# eCOMP0_445 register map
Vendor: Texas Instruments
Peripheral module from a debugger description file (folder msp430).
Registers are 16-bit, read-write, no defined reset value unless marked. A register's access mark holds for its fields unless they carry their own. Offsets are as the file gives them; lines under a group give offsets from that group; [hi:lo] are bit positions; {n}, {i} and the like mark numbered series; 'fields as' and 'values as' point back to an identical list; <NAME> marks a mode.

## eCOMP0
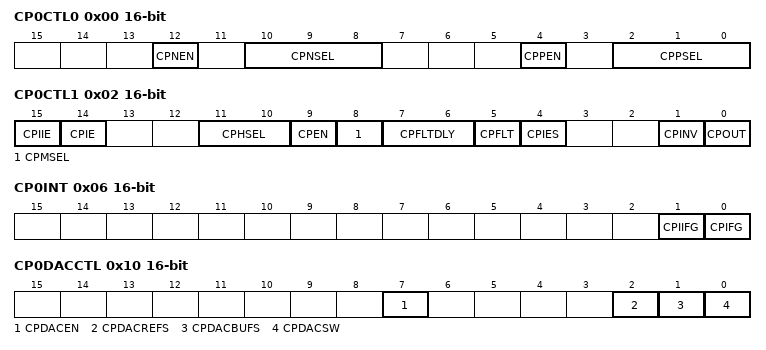
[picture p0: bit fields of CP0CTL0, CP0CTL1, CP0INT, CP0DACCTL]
0x00 CP0CTL0 — Comparator Control Register 0
  [12] CPNEN — Channel input enable for the - terminal
    0=Selected analog input channel for V- terminal is disabled; 1=Selected analog input channel for V- terminal is enabled
  [10:8] CPNSEL — Channel input selected for the - terminal
    {v}=select external input source (v=0..3); 4=device specific, please refer to device data sheet for details; 5=device specific, please refer to device data sheet for details; 6=6-bit DAC
  [4] CPPEN — Channel input enable for the V+ terminal
    0=Selected analog input channel for V+ terminal is disabled; 1=Selected analog input channel for V+ terminal is enabled
  [2:0] CPPSEL — Channel input selected for the V+ terminal
    values as CPNSEL
0x02 CP0CTL1 access per field — Comparator Control Register 1
  [15] CPIIE rw — Comparator inverted interrupt output enable bit
    0=Interrupt inverted output is disabled; 1=Interrupt inverted output is enabled
  [14] CPIE rw — Comparator interrupt output enable bit
    0=Interrupt output is disabled; 1=Interrupt output is enabled
  [11:10] CPHSEL rw — Programable Hysteresis mode. These bits are used to select the Hysteresis mode.
    0=disable; 1=10mV; 2=20mV; 3=30mV
  [9] CPEN rw — Comparator enable/disable. This bit is used to disable/enable the comparator. When the comparator is disabled, the Comparator consumes no power.
    0=Comparator is disabled; 1=Comparator is enabled
  [8] CPMSEL rw — Power mode selection.
    0=High-power & High speed mode (500nA); 1=Low-power & Low speed mode (10nA)
  [7:6] CPFLTDLY rw — Analog Filter Delay selection. These bits are used to select the analog filter delay
    0=Typical filter delay of 450ns; 1=Typical filter delay of 900ns; 2=Typical filter delay of 1800ns; 3=Typical filter delay of 3600ns
  [5] CPFLT rw — Analog Output Low Pass filter Selection. Changing CPFLT might set interrupt flag.
    0=Comparator output is not filtered; 1=Comparator output is filtered
  [4] CPIES rw — Interrupt edge select for CEIIFG and CEIFG
    0=Rising edge for CPIFG, falling edge for CPIIFG; 1=Falling edge for CPIFG, rising edge for CPIIFG
  [1] CPINV rw — Comparator output polarity
    0=Comparator output is non-inverted; 1=Comparator output is inverted
  [0] CPOUT ro — Comparator output value
0x06 CP0INT — Comparator Interrupt Control Register
  [1] CPIIFG — Comparator output inverted interrupt flag
    0=No interrupt pending; 1=Output interrupt pending
  [0] CPIFG — Comparator output interrupt flag
    0=No interrupt pending; 1=Output interrupt pending
0x08 CP0IV ro — Comparator Interrupt Vector Word Register
  [15:0] CPIV — Comparator interrupt vector word register
    0=NONE (No interrupt pending); 2=CPIFG; 4=CPIIFG
0x10 CP0DACCTL — 6-bit Comparator built-in DAC Control Register
  [7] CPDACEN — Comparator built-in DAC output control bit.
    0=DAC output is disabled; 1=DAC output is enabled
  [2] CPDACREFS — Comparator built-in DAC reference voltage selection
    0=VDD selected; 1=on-chip VREF selected
  [1] CPDACBUFS — Comparator built-in DAC buffer controlled source selection.
    0=Comparator output is selected as the buffer control source; 1=CPDACSW bit is selected as the buffer control source
  [0] CPDACSW — This bit is only valid when CPDACBUFS is set to 1.
    0=CPDACBUF1 selected; 1=CPDACBUF2 selected
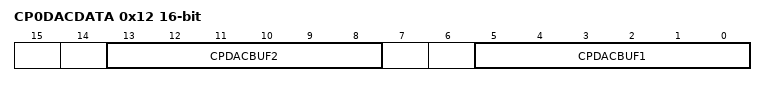
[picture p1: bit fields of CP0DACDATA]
0x12 CP0DACDATA — 6-bit Comparator built-in DAC Data Register
  [13:8] CPDACBUF2 — 2nd 6-bit DAC buffer Data
    0=0v; {v}=selected reference voltage * {v}/64 (v=1..63)
  [5:0] CPDACBUF1 — 1st 6-bit DAC buffer Data
    0=0v; {v}=selected reference voltage * {v}/64 (v=1..8); 9=selected reference voltage *9/64; {v}=selected reference voltage * {v}/64 (v=10..63)
